AUTOSAR XML (schema 4-2-1)
package /MyDataTypes
  base type myuint8: category=FIXED_LENGTH, base-type-size=8, base-type-encoding=NONE, native-declaration=unsigned char
  impl type myuint8: category=VALUE, base-type=myuint8, range phys 0..255, raw 0..255
package /Interfacing
  sender receiver interface SR_Interface_Door_Sensor
    data Sensor_Reading: type=myuint8
  sender receiver interface SR_Interface_Door_State
    data Door_State: type=myuint8
  sender receiver interface SR_Interface_LED_State
    data LED_State: type=myuint8
  client server interface CS_Interface
    operation LED_Switch: possible-error=[E_OK, E_NOT_OK]
      arg LED_State: type=myuint8, direction=IN
    error E_OK: error-code=0
    error E_NOT_OK: error-code=1
package /SWCs
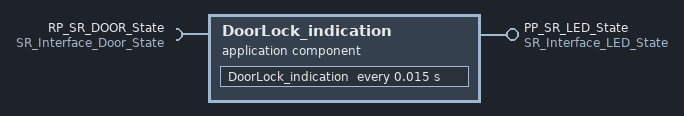
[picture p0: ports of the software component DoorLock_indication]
  application sw component type DoorLock_indication
    provide port PP_SR_LED_State: provided-interface=SR_Interface_LED_State
    require port RP_SR_DOOR_State: required-interface=SR_Interface_Door_State
    behavior IB_DoorLock_indication
      timing event TE_15ms: start-on-event=DoorLock_indication, period=0.015
      runnable DoorLock_indication: symbol=IB_DoorLock_indication_Runnable
        data-read-access:
          access DR_Access: accessed-variable=RP_SR_DOOR_State.Door_State
        data-write-access:
          access DW_Access: accessed-variable=PP_SR_LED_State.LED_State
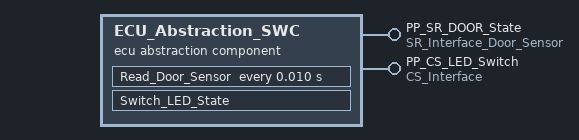
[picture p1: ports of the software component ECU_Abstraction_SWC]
  ecu abstraction sw component type ECU_Abstraction_SWC
    provide port PP_SR_DOOR_State: provided-interface=SR_Interface_Door_Sensor
    provide port PP_CS_LED_Switch: provided-interface=CS_Interface
    behavior IB_ECU_Abstraction_SWC
      timing event TE_10ms: start-on-event=Read_Door_Sensor, period=0.010
      operation invoked event OIE_LED_Switch: start-on-event=Switch_LED_State, operation=PP_CS_LED_Switch.LED_Switch
      runnable Read_Door_Sensor: symbol=Read_Door_Sensor_Runnable
        data-write-access:
          access DW_Access: accessed-variable=PP_SR_DOOR_State.Sensor_Reading
      runnable Switch_LED_State: symbol=Switch_LED_State_Runnable
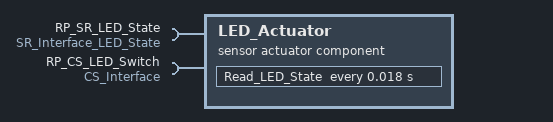
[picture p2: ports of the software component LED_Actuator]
  sensor actuator sw component type LED_Actuator
    require port RP_SR_LED_State: required-interface=SR_Interface_LED_State
    require port RP_CS_LED_Switch: required-interface=CS_Interface
    behavior IB_LED_Actuator
      timing event TE_18ms: start-on-event=Read_LED_State, period=0.018
      runnable Read_LED_State: symbol=Read_LED_State_Runnable
        data-read-access:
          access DR_Access: accessed-variable=RP_SR_LED_State.LED_State
        sync call Sync_Server_Call: operation=RP_CS_LED_Switch.LED_Switch
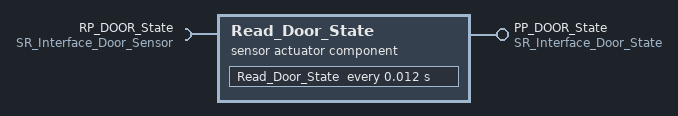
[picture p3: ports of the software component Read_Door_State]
  sensor actuator sw component type Read_Door_State
    provide port PP_DOOR_State: provided-interface=SR_Interface_Door_State
    require port RP_DOOR_State: required-interface=SR_Interface_Door_Sensor
    behavior IB_Read_Door_State
      timing event TE_12ms: start-on-event=Read_Door_State, period=0.012
      runnable Read_Door_State: symbol=Read_Door_State_Runnable
        data-read-access:
          access DR_Access: accessed-variable=RP_DOOR_State.Sensor_Reading
        data-write-access:
          access DW_Access: accessed-variable=PP_DOOR_State.Door_State
package /Composition
  composition sw component type SWC_Composition
    4 x component:
      DoorLock_indication: type=DoorLock_indication
      ECU_Abstraction_SWC: type=ECU_Abstraction_SWC
      Read_Door_State: type=Read_Door_State
      LED_Actuator: type=LED_Actuator
    connect ECU_Abstraction_SWC.PP_SR_DOOR_State -> Read_Door_State.RP_DOOR_State
    connect Read_Door_State.PP_DOOR_State -> DoorLock_indication.RP_SR_DOOR_State
    connect DoorLock_indication.PP_SR_LED_State -> LED_Actuator.RP_SR_LED_State
    connect ECU_Abstraction_SWC.PP_CS_LED_Switch -> LED_Actuator.RP_CS_LED_Switch
